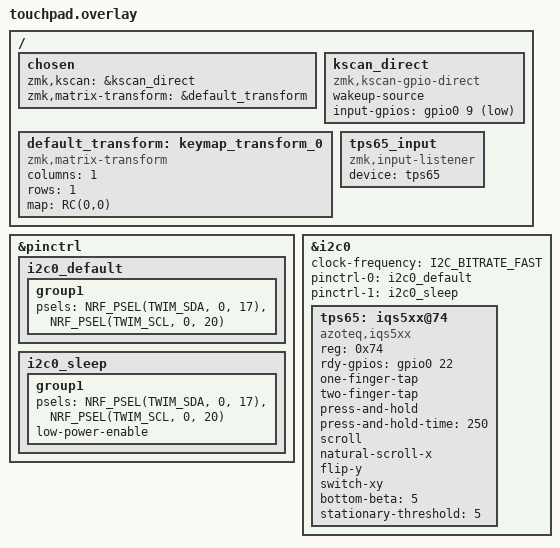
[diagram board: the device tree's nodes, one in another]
/*
 * Standalone BLE Touchpad — TPS65 + NRF52840 SuperMini
 *
 * Wiring:
 *   VCC → 3.3V
 *   GND → GND
 *   SDA → D2 (P0.17)
 *   SCL → D3 (P0.20)
 *   RDY → D4 (P0.22)  ← Required (interrupt-driven)
 *
 * Axis orientation: Length (65mm) runs vertically (Y axis).
 * If movement is inverted or swapped, adjust flip-x/flip-y/switch-xy below.
 */

#include <dt-bindings/zmk/matrix_transform.h>

/ {
    chosen {
        zmk,kscan = &kscan_direct;
        zmk,matrix-transform = &default_transform;
    };

    /* Dummy kscan (required by ZMK) */
    kscan_direct: kscan_direct {
        compatible = "zmk,kscan-gpio-direct";
        wakeup-source;
        input-gpios = <&gpio0 9 (GPIO_ACTIVE_LOW | GPIO_PULL_UP)>;
    };

    default_transform: keymap_transform_0 {
        compatible = "zmk,matrix-transform";
        columns = <1>;
        rows = <1>;
        map = < RC(0,0) >;
    };

    /* Connect touchpad → ZMK input */
    tps65_input: tps65_input {
        compatible = "zmk,input-listener";
        device = <&tps65>;
    };
};

/* Pin control for I2C0 */
&pinctrl {
    i2c0_default: i2c0_default {
        group1 {
            psels = <NRF_PSEL(TWIM_SDA, 0, 17)>,
                    <NRF_PSEL(TWIM_SCL, 0, 20)>;
        };
    };

    i2c0_sleep: i2c0_sleep {
        group1 {
            psels = <NRF_PSEL(TWIM_SDA, 0, 17)>,
                    <NRF_PSEL(TWIM_SCL, 0, 20)>;
            low-power-enable;
        };
    };
};

/* I2C bus — using i2c0 directly with pinctrl */
&i2c0 {
    status = "okay";
    clock-frequency = <I2C_BITRATE_FAST>;

    pinctrl-0 = <&i2c0_default>;
    pinctrl-1 = <&i2c0_sleep>;
    pinctrl-names = "default", "sleep";

    tps65: iqs5xx@74 {
        compatible = "azoteq,iqs5xx";
        reg = <0x74>;
        status = "okay";

        /* RDY pin — required for interrupt-driven operation */
        rdy-gpios = <&gpio0 22 GPIO_ACTIVE_HIGH>;

        /* RESET — optional, uncomment if wired to D5 */
        /* reset-gpios = <&gpio0 24 GPIO_ACTIVE_LOW>; */

        /* Gestures */
        one-finger-tap;
        two-finger-tap;
        press-and-hold;
        press-and-hold-time = <250>;

        /* Scrolling */
        scroll;
        natural-scroll-x;

        /*
         * Axis mapping — TPS65 length (65mm) mounted vertically.
         * Adjust these if axes are swapped or inverted after testing:
         *   flip-x;       ← invert horizontal
         *   flip-y;       ← invert vertical
         *   switch-xy;    ← swap X and Y axes
         */
        flip-y;
        switch-xy;

        /* Tuning */
        bottom-beta = <5>;
        stationary-threshold = <5>;
    };
};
